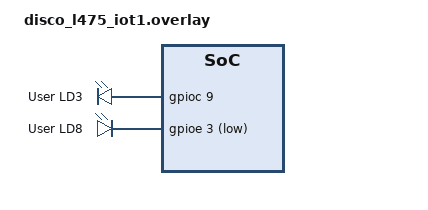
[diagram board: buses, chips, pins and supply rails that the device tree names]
/ {
    leds {
        compatible = "gpio-leds";

        interconnected_led_3: led_3 {
            gpios = <&gpioc 9 GPIO_ACTIVE_HIGH>;
            label = "User LD3";
        };

        gpio_led4: led_4
        {
            gpios = <&gpioe 3 GPIO_ACTIVE_LOW>;
            label = "User LD8";

        };

    };
        

    aliases {
        led2 = &interconnected_led_3;
        led3 = &gpio_led4;
    };
};

